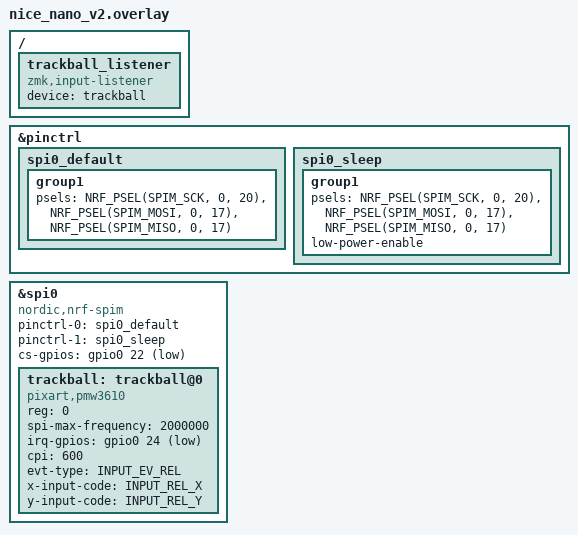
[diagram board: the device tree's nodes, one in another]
/*
 * Copyright (c) 2020 Pete Johanson
 *
 * SPDX-License-Identifier: MIT
 */

#include <zephyr/dt-bindings/input/input-event-codes.h>

// Pin Control (pinctrl) configuration block
&pinctrl {
    // Default configuration for SPI0 pins
    spi0_default: spi0_default {
        group1 {
            psels = <NRF_PSEL(SPIM_SCK, 0, 20)>, // Clock on P0.20
                <NRF_PSEL(SPIM_MOSI, 0, 17)>,    // MOSI on P0.17
                <NRF_PSEL(SPIM_MISO, 0, 17)>;    // MISO on P.017
        };
    };
    // Sleep configuration for SPI0 pins (power saving mode)
    spi0_sleep: spi0_sleep {
        group1 {
            psels = <NRF_PSEL(SPIM_SCK, 0, 20)>, 
                <NRF_PSEL(SPIM_MOSI, 0, 17)>,    
                <NRF_PSEL(SPIM_MISO, 0, 17)>;    
            low-power-enable;
        };
    };
};

// SPI0 Controller Configuration
&spi0 {
    status = "okay";  // Enable this SPI controller
    compatible = "nordic,nrf-spim";  // Specify the Nordic SPI controller type
    pinctrl-0 = <&spi0_default>;     // Use default pin configuration
    pinctrl-1 = <&spi0_sleep>;       // Use sleep pin configuration when in sleep mode
    pinctrl-names = "default", "sleep"; 
    // Chip Select (nCS) pin configuration
    cs-gpios = <&gpio0 22 GPIO_ACTIVE_LOW>;

    // Trackball device configuration
    trackball: trackball@0 {
        status = "okay";
        compatible = "pixart,pmw3610";
        reg = <0>;
        spi-max-frequency = <2000000>;
        // Motion sensor on P0.24 
        irq-gpios = <&gpio0 24 (GPIO_ACTIVE_LOW | GPIO_PULL_UP)>;
        cpi = <600>;
        evt-type = <INPUT_EV_REL>;
        x-input-code = <INPUT_REL_X>;
        y-input-code = <INPUT_REL_Y>;
    };
};

/ {
  trackball_listener {
    compatible = "zmk,input-listener";
    device = <&trackball>;
  };
};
